# CY8C5888LTI_LP097 register map
File version: 0.1
Registers are 8-bit, read-write, no defined reset value unless marked. A register's access mark holds for its fields unless they carry their own. Offsets are from the block's base; [hi:lo] are bit positions; {n}, {i} and the like mark numbered series; 'fields as' and 'values as' point back to an identical list.

## I2C_Slave
Base 0x00000000
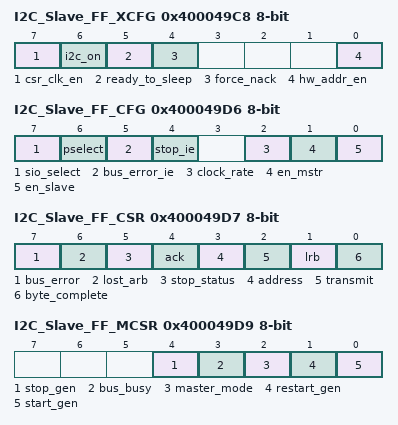
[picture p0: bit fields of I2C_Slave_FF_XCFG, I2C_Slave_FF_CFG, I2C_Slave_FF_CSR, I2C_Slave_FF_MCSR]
0x400049C8 I2C_Slave_FF_XCFG — I2C Extended Configuration Register
  [7] csr_clk_en — This bit is used for gating system clock for the blocks core logic that is not associated with AHB interface. Clock is made available to the core logic only when this bit is set to 1 and the input pin ext_clk_en is also active. If either of them is not active, the blocks core logic does not receive the system clock.
  [6] i2c_on — This bit should be set by the user during initial block configuration if the user wants to use the I2C block as wake-up source. Only when this bit set along with other bits mentioned in the sleep mode section, the I2C wakes up system from sleep on address match.
  [5] ready_to_sleep ro — Once the user sets the force_nack bit, the I2C block sets this bit if I2C is not busy or it waits for ongoing transaction to be completed and then sets this bit. As long as this bit is set, the I2C block is going to nack all the transactions.Clearing force_nack bit automatically clears this bit. HW clears this bit automatically on assertion of PD (Power Down)
  [4] force_nack — This bit must be set by the user before putting the device to sleep and wait for ready_to_sleep status bit to be set. This can be cleared by user by writing '0' and the HW clears it automatically on assertion of PD(Power Down)
  [0] hw_addr_en — When this bit is set to a '1', hardware address compare is enabled. On an address match, an interrupt is generated, CSR register bit 3 is set, and the clock is stalled until the CPU writes a 0 into the CSR register bit 3. The address is automatically ACKed on a match. On an address mismatch,no interrupt is generated, clock is not stalled, and bit 3 in the CSR register is set. The CPU must write a 0 into the CSR register bit 3 to clear it. The address is automatically NACKed on a mismatch. You must configure the compare address in the ADR register. When this bit is set to a '0', software address compare is enabled. An interrupt is generated, the clock is stalled, and CSR register bit 3 is set when the received address byte is available in the Data register; to enable the CPU to do a firmware address compare. The clock is stalled until the CPU writes a 0 into the CSR register bit 3. The functionality of this bit is independent of the data buffering mode.
0x400049CA I2C_Slave_FF_ADDR — I2C Slave Adddress Register
  [6:0] slave_address — These seven bits hold the slave's own device address. These bits are held zero if I2C_CFG.en_mstr and I2C_CFG.en_slave are both zero.
0x400049D6 I2C_Slave_FF_CFG — I2C Configuration Register
  [7] sio_select — I2C Pin Select for SCL/SDA lines from SIO1/SIO2, 0 = SCL and SDA lines get their inputs from SIO1 module.sclk_str1 and sda_ack1 are driven to SIO1 module and they get asserted once device wakes up from sleep. 1 = SCL and SDA lines get their inputs from SIO2 module. sclk_str2 and sda_ack2 are driven to SIO2 module and they get asserted once device wakes up from sleep. This bit is valid only when I2C.CFG[6] is asserted.
  [6] pselect — I2C Pin Select for SCL/SDA lines from GPIO/SIO, 0 = SCL and SDA lines get their inputs from GPIO module.sclk_str0 and sda_ack0 are driven to GPIO module and they get asserted once device wakes up from sleep. 1 = SCL and SDA lines get their inputs from one of the SIO Blocks that is chosen based on the configuration of bit I2C.CFG[7]
  [5] bus_error_ie — Bus Error Interrupt Enable 0 disabled 1 enabled. An interrupt is generated on the detection of a Bus error condition.
  [4] stop_ie — Stop Interrupt Enable 0 disabled 1 enabled. An interrupt is generated on the detection of a Stop condition.
  [2] clock_rate — 0 Samples/bit is 16, 1 Samples/bit is 32
  [1] en_mstr — Enables master mode for the device
  [0] en_slave — Enables Slave mode for the device
0x400049D7 I2C_Slave_FF_CSR — I2C Control and Status Register
  [7] bus_error — It must be cleared by firmware by writing a '0' to the bit position. It is never cleared by the hardware. 1 a misplaced Start or Stop condition was detected. This bit is held zero if I2C_CFG.en_mstr and I2C_CFG.en_slave are both zero.
  [6] lost_arb — This bit is set immediately on lost arbitration; however, it does not cause an interrupt. This status may be checked after the following Byte Complete interrupt. Any Start detect or a write to the Start or Restart generate bits (MCSR register), when operating in Master mode, will also clear the bit. 1 lost Arbitration. This bit is held zero if I2C_CFG.en_mstr is zero.
  [5] stop_status — It must be cleared by firmware with write of '0' to the bit position. It is never cleared by the hardware. 1 a Stop condition was detected. This bit is held zero if I2C_CFG.en_mstr and I2C_CFG.en_slave are both zero.
  [4] ack — Acknowledge Out. Bit is automatically cleared by hardware on a Byte Complete event. 0 nack the last received byte. 1 ack the last received byte
  [3] address — It must be cleared by firmware with write of '0' to the bit position. 1 the received byte is a slave address. This bit is held zero if I2C_CFG.en_mstr and I2C_CFG.en_slave are both zero
  [2] transmit — Bit is set by firmware to define the direction of the byte transfer. Any Start detect will clear the bit. 0 receive mode 1 transmit mode. This bit is held zero if I2C_CFG.en_mstr and I2C_CFG.en_slave are both zero.
  [1] lrb — Last Received Bit. The value of the 9th bit in a Transmit sequence, which is the acknowledge bit from the receiver. Any Start detect or a write to the Start or Restart generate bits, when operating in Master mode, will also clear the bit. 0 last transmitted byte was ACK'ed by the receiver. 1 last transmitted byte was NACK'ed by the receiver. This bit is held zero if I2C_CFG.en_mstr and I2C_CFG.en_slave are both zero.
  [0] byte_complete — Transmit/Receive Mode: 0 no completed transmit/receive since last cleared by firmware. Any Start detect or a write to the start or Restart generate bits, when operating in Master mode, will also clear the bit. Transmit mode: 1 eight bits of data have been transmitted and an ACK or NACK has been received. Receive mode: 1 eight bits of data have been received. This bit is held zero if I2C_CFG.en_mstr and I2C_CFG.en_slave are both zero.
0x400049D8 I2C_Slave_FF_DATA — I2C Data Register
  [7:0] data — Read received data or write data to transmit. These bits are held zero if I2C_CFG.en_mstr and I2C_CFG.en_slave are both zero.
0x400049D9 I2C_Slave_FF_MCSR — Master Control and Status Register: I2C_MCSR
  [4] stop_gen — This bit is set only for master transmitter and used at the end of byte transfer. After byte complete status is set, if this bit is set followed by the Transmit bit in I2C.CSR register, Stop condition is generated after byte complete. This bit is automatically reset to 0 after the Stop, start or Restart has been generated. During data phase, if Stop Gen bit is set to 0, clearing the Transmit bit in I2C.CSR register will also generate a Stop condition. This bit is held zero if I2C_CFG.en_mstr and I2C_CFG.en_slave are both zero.
  [3] bus_busy ro — This bit is set to the following. 0 when a Stop condition is detected (from any bus master). 1 when a Start condition is detected (from any bus master). This bit is held zero if I2C_CFG.en_mstr and I2C_CFG.en_slave are both zero.
  [2] master_mode ro — This bit is set/cleared by hardware when the device is operating as a master. 0 stop condition detected, generated by this device. 1 start condition detected, generated by this device. This bit is held zero if I2C_CFG.en_mstr and I2C_CFG.en_slave are both zero.
  [1] restart_gen — This bit is cleared by hardware when the Restart generation is complete. 0 restart generation complete. 1 generate a Restart condition. This bit is held zero if I2C_CFG.en_mstr and I2C_CFG.en_slave are both zero.
  [0] start_gen — This bit is cleared by hardware when the Start generation is complete. 0 start generation complete. 1 generate a Start condition and send a byte (address) to the I2C bus, if bus is not busy. This bit is held zero if I2C_CFG.en_mstr and I2C_CFG.en_slave are both zero.
0x400049DB I2C_Slave_FF_CLK_DIV1 — I2C Clock Divide Factor Register-1
  [7:0] Div — The configuration of this register along with that in register CLK_DIV2 defines the factor by which the SYSCLK will be divided in the I2C block. These bits are held zero if I2C_CFG.en_mstr and I2C_CFG.en_slave are both zero.
0x400049DC I2C_Slave_FF_CLK_DIV2 — I2C Clock Divide Factor Register-2
  [1:0] Div — The configuration of this register along with that in register CLK_DIV1 defines the factor by whichthe SYSCLK will be divided in the I2C block. These bits are held zero if I2C_CFG.en_mstr and I2C_CFG.en_slave are both zero.
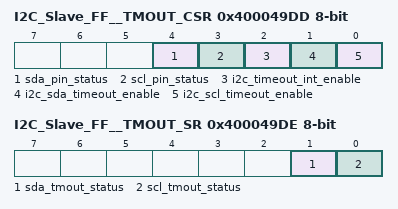
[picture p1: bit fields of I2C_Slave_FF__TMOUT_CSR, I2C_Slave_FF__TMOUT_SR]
0x400049DD I2C_Slave_FF__TMOUT_CSR — I2C Timerout Control and Status Register
  [4] sda_pin_status — SDA Line status.
  [3] scl_pin_status — SCL Line status.
  [2] i2c_timeout_int_enable ro — I2C Timeout interrupt enable.
  [1] i2c_sda_timeout_enable
  [0] i2c_scl_timeout_enable
0x400049DE I2C_Slave_FF__TMOUT_SR — I2C Timerout Status Register
  [1] sda_tmout_status — SDA Timeout status.
  [0] scl_tmout_status — SCL Timeout status.
0x400049DF I2C_Slave_FF__TMOUT_CFG0 — I2C Timerout Period Configuration Register-0
  [7:0] timeout_period_lowbyte — The configuration of this register along with that in register TMOUT_CFG1 to define the number units before SCL or SDA stuck low timeout triggers the I2C interrupt. The one unit is equal to SYSCLK/1024. The TMOUT_CFG0 defines lower byte of the period.
0x400049E0 I2C_Slave_FF__TMOUT_CFG1 — Extended Configuration Register: TMOUT_CFG1
  [3:0] timeout_period_highnibble — The configuration of this register along with that in register TMOUT_CFG1 to define the number units before SCL or SDA stuck low timeout triggers the I2C interrupt. The one unit is equal to SYSCLK/1024. The TMOUT_CFG1 defines higher octet of the period.

## UART
Base 0x00000000
0x4000644C TX_UART_TX_DATA — TX Data Register
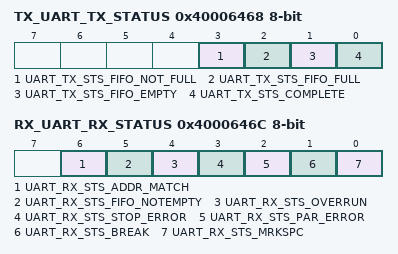
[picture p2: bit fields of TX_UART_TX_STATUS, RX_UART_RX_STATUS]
0x40006468 TX_UART_TX_STATUS — TX status register
  [3] UART_TX_STS_FIFO_NOT_FULL ro, [2] UART_TX_STS_FIFO_FULL ro, [1] UART_TX_STS_FIFO_EMPTY ro, [0] UART_TX_STS_COMPLETE ro
0x4000646C RX_UART_RX_STATUS — RX status register
  [6] UART_RX_STS_ADDR_MATCH ro, [5] UART_RX_STS_FIFO_NOTEMPTY ro, [4] UART_RX_STS_OVERRUN ro, [3] UART_RX_STS_STOP_ERROR ro, [2] UART_RX_STS_PAR_ERROR ro, [1] UART_RX_STS_BREAK ro, [0] UART_RX_STS_MRKSPC ro
0x4000652A RX_UART_RX_ADDRESS1 — RX Address1 Register
0x4000653A RX_UART_RX_ADDRESS2 — RX Address2 Register
0x4000654A RX_UART_RX_DATA — RX Data Register

## Opamp
Base 0x00000000
0x400043A4 PM_ACT_CFG4 — Active Power Mode Configuration Register 4
  [3:0] EN_OPAMP — Enables subsystems during active power mode
    0=Blk_0 (Enables analog linear output buffer for Opamp block 0); 2=Blk_1 (Enables analog linear output buffer for Opamp block 1); 4=Blk_2 (Enables analog linear output buffer for Opamp block 2); 8=Blk_3 (Enables analog linear output buffer for Opamp block 3)
0x400043B4 PM_STBY_CFG4 — Standby Power Mode Configuration Register 4
  [3:0] EN_OPAMP — Enables subsystems during standby power mode
    values as PM_ACT_CFG4.EN_OPAMP
0x40004626 OPAMP__TR0 — Analog Output Buffer Trim Register 0
  [4:0] offset_trim — Offset Trim: 420uV typical step size; +/- 6.8mV offset trimmable range
0x40004627 OPAMP__TR1 — Analog Output Buffer Trim Register 1
0x4000585E OPAMP__CR — Analog Output Buffer Configuration Register
  [1:0] pwr_mode — Power Mode
    0=Default_Fast (Default Power mode Fast); 1=Slow (Power Mode Slow); 2=Medium (Power Mode Medium); 3=Fast (Power Mode Fast)
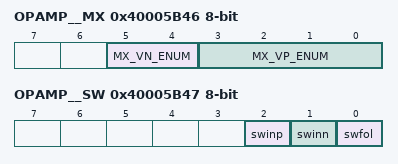
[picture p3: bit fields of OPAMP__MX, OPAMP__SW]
0x40005B46 OPAMP__MX — Analog Buffer Input Selection Register
  [5:4] MX_VN_ENUM — MUX select VN (Negative terminal input)
    0=OPAMP0_MX_VN_DEFAULT (Default - Not Connected (NC)); 1=OPAMP0_MX_VN_AG4 (MUX Selection AGL(4)); 2=OPAMP0_MX_VN_AG6 (MUX Selection AGL(6)); 3=OPAMP0_MX_VN_0x3 (Reserved (NC))
  [3:0] MX_VP_ENUM — MUX select VP (Positive terminal input)
    0=OPAMP0_MX_VP_DEFAULT (Default - Not Connected (NC)); {v}=OPAMP0_MX_VP_AG{v+3} (MUX Selection AGL({v+3})) (v=1..4); {v}=OPAMP0_MX_VP_ABUS{v-5} (MUX Selection ABUSL({v-5})) (v=5..8); 9=OPAMP0_MX_VP_VREF (MUX Selection: OPAMP Voltage Reference); {v}=OPAMP0_MX_VP_H_{0x0+v} (Reserved (NC)) (v=10..15)
0x40005B47 OPAMP__SW — Analog Buffer Routing Switch Register
  [2] swinp — Switch Enable Positive Input
  [1] swinn — Switch Enable Negative Input
  [0] swfol — Switch Enable Follow

## Grip_Control_En
Base 0x00000000
0x4000647C Grip_Control_En_CONTROL_REG

## ADC — SAR ADC
Base 0x00000000
0x40004614 SAR_TR0 — SAR trim register
{0x40005900+i} SAR_CSR{i} (i=0..6) — SAR status and control register {i}
0x40005B20 SAR_SW0 — SAR Analog Routing Register 0
{0x40005B20+i} SAR_SW{i} (i=2..4) — SAR Analog Routing Register {i}
0x40005B26 SAR_SW6 — SAR Analog Routing Register 6
0x40005B27 SAR_CLK — SAR Clock Selection Register
0x40005BA0 SAR_WRK 16-bit — SAR working register
